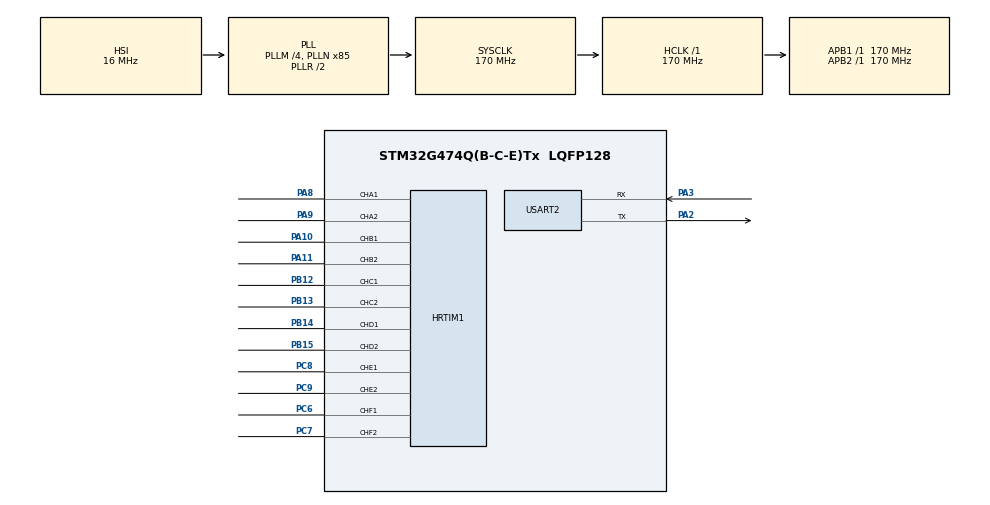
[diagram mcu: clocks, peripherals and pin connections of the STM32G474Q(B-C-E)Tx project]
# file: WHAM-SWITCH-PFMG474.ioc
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HRTIM1.PrescalerRatio_MASTER=HRTIM_PRESCALERRATIO_DIV1
HRTIM1.PrescalerRatio_TA=HRTIM_PRESCALERRATIO_DIV1
HRTIM1.PrescalerRatio_TB=HRTIM_PRESCALERRATIO_DIV1
HRTIM1.PrescalerRatio_TC=HRTIM_PRESCALERRATIO_DIV1
HRTIM1.PrescalerRatio_TD=HRTIM_PRESCALERRATIO_DIV1
HRTIM1.PrescalerRatio_TE=HRTIM_PRESCALERRATIO_DIV1
HRTIM1.PrescalerRatio_TF=HRTIM_PRESCALERRATIO_DIV1
Mcu.Family=STM32G4
Mcu.Name=STM32G474Q(B-C-E)Tx
Mcu.Package=LQFP128
NVIC.PriorityGroup=NVIC_PRIORITYGROUP_4
PA10.Mode=Output_TB1TB2
PA10.Signal=HRTIM1_CHB1
PA11.Mode=Output_TB1TB2
PA11.Signal=HRTIM1_CHB2
PA2.Mode=Asynchronous
PA2.Signal=USART2_TX
PA3.Mode=Asynchronous
PA3.Signal=USART2_RX
PA8.Mode=Output_TA1TA2
PA8.Signal=HRTIM1_CHA1
PA9.Mode=Output_TA1TA2
PA9.Signal=HRTIM1_CHA2
PB12.Mode=Output_TC1TC2
PB12.Signal=HRTIM1_CHC1
PB13.Mode=Output_TC1TC2
PB13.Signal=HRTIM1_CHC2
PB14.Mode=Output_TD1TD2
PB14.Signal=HRTIM1_CHD1
PB15.Mode=Output_TD1TD2
PB15.Signal=HRTIM1_CHD2
PC6.Mode=Output_TF1TF2
PC6.Signal=HRTIM1_CHF1
PC7.Mode=Output_TF1TF2
PC7.Signal=HRTIM1_CHF2
PC8.Mode=Output_TE1TE2
PC8.Signal=HRTIM1_CHE1
PC9.Mode=Output_TE1TE2
PC9.Signal=HRTIM1_CHE2
ProjectManager.HeapSize=0x200
ProjectManager.StackSize=0x400
ProjectManager.TargetToolchain=STM32CubeIDE
RCC.AHBFreq_Value=170000000
RCC.APB1Freq_Value=170000000
RCC.APB1TimFreq_Value=170000000
RCC.APB2Freq_Value=170000000
RCC.APB2TimFreq_Value=170000000
RCC.CortexFreq_Value=170000000
RCC.EXTERNAL_CLOCK_VALUE=12288000
RCC.HCLKFreq_Value=170000000
RCC.HSE_VALUE=8000000
RCC.HSI48_VALUE=48000000
RCC.HSI_VALUE=16000000
RCC.LSE_VALUE=32768
RCC.PLLM=RCC_PLLM_DIV4
RCC.PLLN=85
RCC.SYSCLKFreq_VALUE=170000000
RCC.SYSCLKSource=RCC_SYSCLKSOURCE_PLLCLK
RCC.USBFreq_Value=170000000
RCC.VCOOutputFreq_Value=340000000
USART2.VirtualMode-Asynchronous=VM_ASYNC
VP_HRTIM1_VS_hrtimMasterTimerNoOutput.Mode=MasterTimer
VP_SYS_VS_DBSignals.Mode=DisableDeadBatterySignals
board=custom

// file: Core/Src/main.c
/* USER CODE BEGIN Header */
/**
  ******************************************************************************
  * @file           : main.c
  * @brief          : Main program body
  ******************************************************************************
  * @attention
  *
  * Copyright (c) 2026 STMicroelectronics.
  * All rights reserved.
  *
  * This software is licensed under terms that can be found in the LICENSE file
  * in the root directory of this software component.
  * If no LICENSE file comes with this software, it is provided AS-IS.
  *
  ******************************************************************************
  */
/* USER CODE END Header */
#include "main.h"

/* USER CODE BEGIN Includes */
#include "app.h"
#include "boot_jump.h"
#include "board_io.h"
#include "hrtim_hw.h"
#include "mcu.h"
#include "uart_hw.h"
/* USER CODE END Includes */

UART_HandleTypeDef huart2;

void SystemClock_Config(void);
static void MX_GPIO_Init(void);
static void MX_USART2_UART_Init(void);
static void MX_HRTIM1_Init(void);

int main(void)
{

  /* USER CODE BEGIN 1 */

  /* Must be the very first thing that runs -- before HAL_Init() and
     therefore before any clock/peripheral configuration. See
     boot_jump.c: if cmd_boot() (over USART2) requested a bootloader
     entry on the last reset, this diverts into the ROM bootloader from
     this still-clean, just-reset state and never returns. Otherwise it
     returns immediately (always the case when BOOT_JUMP_FEATURE_ENABLED
     is 0) and startup proceeds normally below -- unconditional on
     purpose, so this call site never needs its own #if. */
  BootJump_CheckAndEnter();

  /* USER CODE END 1 */

  /* MCU Configuration--------------------------------------------------------*/

  /* Reset of all peripherals, Initializes the Flash interface and the Systick. */
  HAL_Init();

  /* USER CODE BEGIN Init */
  /* Must run immediately after HAL_Init() -- HAL_InitTick() (called
     inside HAL_Init()) sets SysTick to its default TICK_INT_PRIORITY
     (15, the lowest possible), which this overrides. See
     Mcu_SetSysTickHighestPriority()'s own doc comment (mcu.c) for the full
     priority-inversion window this closes -- placed here, as early as
     possible, so nothing between here and HRTIM1_EnableMasterInterrupt()
     (which sets HRTIM1_Master_IRQn's priority, later in USER CODE 2)
     can be exposed to it, however briefly. Ported from the sibling
     PFM-STM32G474 project's main.c, same placement. */
  Mcu_SetSysTickHighestPriority();
  /* USER CODE END Init */

  /* Configure the system clock */
  SystemClock_Config();

  /* Initialize all configured peripherals */
  MX_GPIO_Init();
  MX_HRTIM1_Init();
  MX_USART2_UART_Init();
  /* USER CODE BEGIN 2 */
  uart_bind(&uart2, &huart2);
  App_Init();
  /* USER CODE END 2 */

  /* Infinite loop */
  while (1)
  {

    /* USER CODE BEGIN 3 */
    App_Poll();
  }
  /* USER CODE END 3 */
}

void SystemClock_Config(void)
{
  RCC_OscInitTypeDef RCC_OscInitStruct = {0};
  RCC_ClkInitTypeDef RCC_ClkInitStruct = {0};

  /* Copied directly from the sibling PFM-STM32G474 project's
     SystemClock_Config() (170 MHz HSI/PLL config), not derived via
     CubeMX's own auto-resolve -- see AGENTS.md / docs/changelog.txt for
     why: enabling HRTIM1 through the CubeMX GUI on 2026-09-04 triggered
     its "resolve clock issues" auto-fix, which silently picked its own
     unrelated 104 MHz PLL config (PLLN=13) instead. hrtim.c's whole
     timing model -- HRTIM_TIMER_CLK_HZ, the hardcoded Period=1699 for
     100 kHz, the 17-count/100 ns dead time -- assumes exactly this
     170 MHz derivation (HSI 16 MHz / PLLM 4 * PLLN 85 / PLLR 2), matching
     V3's real, hardware-verified config. Voltage scale BOOST and
     FLASH_LATENCY_8 are both required at this SYSCLK -- don't drop
     either while "simplifying" this. */

  /** Configure the main internal regulator output voltage
  */
  HAL_PWREx_ControlVoltageScaling(PWR_REGULATOR_VOLTAGE_SCALE1_BOOST);

  /** Initializes the RCC Oscillators according to the specified parameters
  * in the RCC_OscInitTypeDef structure.
  */
  RCC_OscInitStruct.OscillatorType = RCC_OSCILLATORTYPE_HSI;
  RCC_OscInitStruct.HSIState = RCC_HSI_ON;
  RCC_OscInitStruct.HSICalibrationValue = RCC_HSICALIBRATION_DEFAULT;
  RCC_OscInitStruct.PLL.PLLState = RCC_PLL_ON;
  RCC_OscInitStruct.PLL.PLLSource = RCC_PLLSOURCE_HSI;
  RCC_OscInitStruct.PLL.PLLM = RCC_PLLM_DIV4;
  RCC_OscInitStruct.PLL.PLLN = 85;
  RCC_OscInitStruct.PLL.PLLP = RCC_PLLP_DIV2;
  RCC_OscInitStruct.PLL.PLLQ = RCC_PLLQ_DIV2;
  RCC_OscInitStruct.PLL.PLLR = RCC_PLLR_DIV2;
  if (HAL_RCC_OscConfig(&RCC_OscInitStruct) != HAL_OK)
  {
    Error_Handler();
  }

  /** Initializes the CPU, AHB and APB buses clocks
  */
  RCC_ClkInitStruct.ClockType = RCC_CLOCKTYPE_HCLK|RCC_CLOCKTYPE_SYSCLK
                              |RCC_CLOCKTYPE_PCLK1|RCC_CLOCKTYPE_PCLK2;
  RCC_ClkInitStruct.SYSCLKSource = RCC_SYSCLKSOURCE_PLLCLK;
  RCC_ClkInitStruct.AHBCLKDivider = RCC_SYSCLK_DIV1;
  RCC_ClkInitStruct.APB1CLKDivider = RCC_HCLK_DIV1;
  RCC_ClkInitStruct.APB2CLKDivider = RCC_HCLK_DIV1;

  if (HAL_RCC_ClockConfig(&RCC_ClkInitStruct, FLASH_LATENCY_8) != HAL_OK)
  {
    Error_Handler();
  }
}

static void MX_HRTIM1_Init(void)
{
  HRTIM1_FullInit();
}

static void MX_USART2_UART_Init(void)
{

  /* USER CODE BEGIN USART2_Init 1 */
  /* huart2.Init.BaudRate below is hand-set to 115200 -- raised from
     9600 on 2026-09-04 after a real-hardware experiment (9600 -> clean
     at 115200 -> garbled/mismatched at 921600, see docs/changelog.txt)
     specifically to speed up TABLE:STEP uploads (~20s -> ~3.3s for a
     500-entry table). This is a deliberate WHAM-HBRIDGE-PFMG474-only
     divergence from the sibling PFM-STM32G474 project, which still
     uses 9600 -- do not "fix" this to match V3 without checking
     docs/changelog.txt first. python/wham_serial_flash.py and
     python/pfm_table_upload.py's own APP_BAUD constants were updated
     to match; scpi.py takes baud on its own command line.

     This line lives in CubeMX-generated code, OUTSIDE any USER CODE
     marker -- a "Generate Code" from the .ioc (which has no explicit
     baud rate of its own) would reset it back to HAL's default. As it
     happens HAL's default IS 115200 right now, so a regen wouldn't be
     visibly wrong today -- but that's a coincidence, not a guarantee:
     if this value ever needs to change again, re-apply it here
     explicitly rather than trusting a regen to land on the right
     number by chance. */
  /* USER CODE END USART2_Init 1 */
  huart2.Instance = USART2;
  huart2.Init.BaudRate = 115200;
  huart2.Init.WordLength = UART_WORDLENGTH_8B;
  huart2.Init.StopBits = UART_STOPBITS_1;
  huart2.Init.Parity = UART_PARITY_NONE;
  huart2.Init.Mode = UART_MODE_TX_RX;
  huart2.Init.HwFlowCtl = UART_HWCONTROL_NONE;
  huart2.Init.OverSampling = UART_OVERSAMPLING_16;
  huart2.Init.OneBitSampling = UART_ONE_BIT_SAMPLE_DISABLE;
  huart2.Init.ClockPrescaler = UART_PRESCALER_DIV1;
  huart2.AdvancedInit.AdvFeatureInit = UART_ADVFEATURE_NO_INIT;
  if (HAL_UART_Init(&huart2) != HAL_OK)
  {
    Error_Handler();
  }
  if (HAL_UARTEx_SetTxFifoThreshold(&huart2, UART_TXFIFO_THRESHOLD_1_8) != HAL_OK)
  {
    Error_Handler();
  }
  if (HAL_UARTEx_SetRxFifoThreshold(&huart2, UART_RXFIFO_THRESHOLD_1_8) != HAL_OK)
  {
    Error_Handler();
  }
  if (HAL_UARTEx_DisableFifoMode(&huart2) != HAL_OK)
  {
    Error_Handler();
  }
  /* USER CODE BEGIN USART2_Init 2 */
  /* Required for uart.c's interrupt-driven receive (HAL_UART_Receive_IT)
     to actually fire HAL_UART_RxCpltCallback() -- without this, RX
     interrupts never reach the NVIC and the serial command parser
     never receives anything. Ported from the sibling PFM-STM32G474
     project, which hit exactly this failure mode.

     Priority 3 (was 2), moved down the same day HRTIM1_Master_IRQn
     moved from 1 to 2 (see that function's own doc comment in
     hrtim.c for why) -- keeps USART2 strictly below every other
     interrupt in this project's scheme, unchanged in relative
     position, just renumbered to make room. */
  HAL_NVIC_SetPriority(USART2_IRQn, 3U, 0U);
  HAL_NVIC_EnableIRQ(USART2_IRQn);
  /* USER CODE END USART2_Init 2 */

}

static void MX_GPIO_Init(void)
{

  /* GPIO Ports Clock Enable */
  __HAL_RCC_GPIOA_CLK_ENABLE();

  /* USER CODE BEGIN MX_GPIO_Init_2 */

  BoardIo_Init();

  /* USER CODE END MX_GPIO_Init_2 */
}

void Error_Handler(void)
{
  __disable_irq();
  while (1)
  {
  }
}
